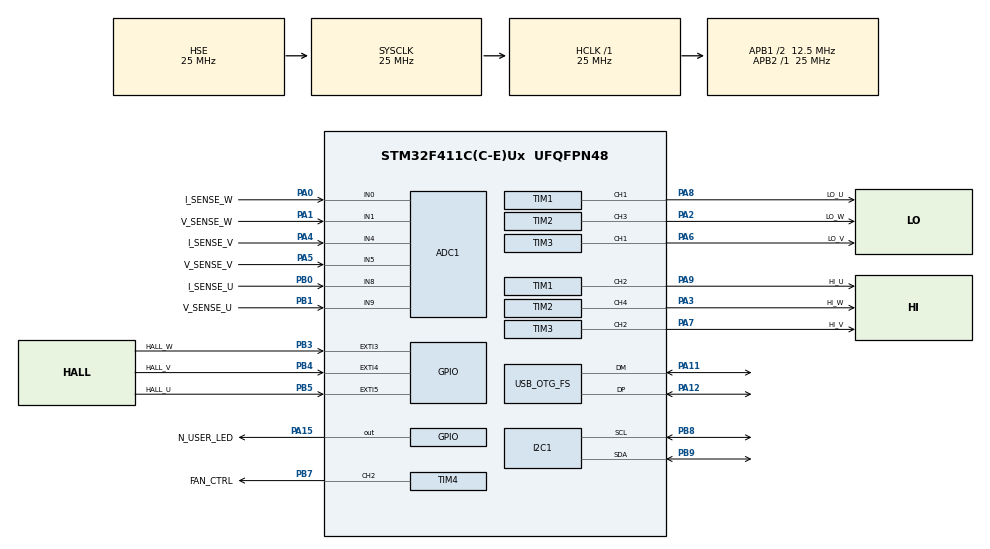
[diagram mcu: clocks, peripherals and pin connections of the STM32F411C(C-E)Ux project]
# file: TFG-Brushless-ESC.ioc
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ADC1.Channel-2\#ChannelRegularConversion=ADC_CHANNEL_0
ADC1.NbrOfConversionFlag=1
ADC1.Rank-2\#ChannelRegularConversion=1
ADC1.SamplingTime-2\#ChannelRegularConversion=ADC_SAMPLETIME_3CYCLES
ADC1.master=1
Mcu.Family=STM32F4
Mcu.Name=STM32F411C(C-E)Ux
Mcu.Package=UFQFPN48
NVIC.EXTI9_5_IRQn=true\:0\:0\:false\:false\:true\:true\:true\:true
NVIC.OTG_FS_IRQn=true\:0\:0\:false\:false\:true\:false\:true\:true
NVIC.PriorityGroup=NVIC_PRIORITYGROUP_4
PA0-WKUP.GPIO_Label=I_SENSE_W
PA0-WKUP.Signal=ADCx_IN0
PA1.GPIO_Label=V_SENSE_W
PA1.Signal=ADCx_IN1
PA11.Mode=Device_Only
PA11.Signal=USB_OTG_FS_DM
PA12.Mode=Device_Only
PA12.Signal=USB_OTG_FS_DP
PA13.Mode=Serial_Wire
PA13.Signal=SYS_JTMS-SWDIO
PA14.Mode=Serial_Wire
PA14.Signal=SYS_JTCK-SWCLK
PA15.GPIO_Label=N_USER_LED
PA15.Signal=GPIO_Output
PA2.GPIO_Label=LO_W
PA2.Signal=S_TIM2_CH3
PA3.GPIO_Label=HI_W
PA3.Signal=S_TIM2_CH4
PA4.GPIO_Label=I_SENSE_V
PA4.Signal=ADCx_IN4
PA5.GPIO_Label=V_SENSE_V
PA5.Signal=ADCx_IN5
PA6.GPIO_Label=LO_V
PA6.Signal=S_TIM3_CH1
PA7.GPIO_Label=HI_V
PA7.Signal=S_TIM3_CH2
PA8.GPIO_Label=LO_U
PA8.Signal=S_TIM1_CH1
PA9.GPIO_Label=HI_U
PA9.Signal=S_TIM1_CH2
PB0.GPIO_Label=I_SENSE_U
PB0.Signal=ADCx_IN8
PB1.GPIO_Label=V_SENSE_U
PB1.Signal=ADCx_IN9
PB3.GPIO_Label=HALL_W
PB3.Signal=GPXTI3
PB4.GPIO_Label=HALL_V
PB4.Signal=GPXTI4
PB5.GPIO_Label=HALL_U
PB5.Signal=GPXTI5
PB7.GPIO_Label=FAN_CTRL
PB7.Signal=S_TIM4_CH2
PB8.Mode=I2C
PB8.Signal=I2C1_SCL
PB9.Mode=I2C
PB9.Signal=I2C1_SDA
PC14-OSC32_IN.Mode=LSE-External-Oscillator
PC14-OSC32_IN.Signal=RCC_OSC32_IN
PC15-OSC32_OUT.Mode=LSE-External-Oscillator
PC15-OSC32_OUT.Signal=RCC_OSC32_OUT
PH0\ -\ OSC_IN.Mode=HSE-External-Oscillator
PH0\ -\ OSC_IN.Signal=RCC_OSC_IN
PH1\ -\ OSC_OUT.Mode=HSE-External-Oscillator
PH1\ -\ OSC_OUT.Signal=RCC_OSC_OUT
ProjectManager.HeapSize=0x200
ProjectManager.StackSize=0x400
ProjectManager.TargetToolchain=STM32CubeIDE
RCC.48MHZClocksFreq_Value=48000000
RCC.AHBFreq_Value=25000000
RCC.APB1CLKDivider=RCC_HCLK_DIV2
RCC.APB1Freq_Value=12500000
RCC.APB1TimFreq_Value=25000000
RCC.APB2Freq_Value=25000000
RCC.APB2TimFreq_Value=25000000
RCC.CortexFreq_Value=25000000
RCC.HCLKFreq_Value=25000000
RCC.HSE_VALUE=25000000
RCC.HSI_VALUE=16000000
RCC.PLLM=25
RCC.PLLN=144
RCC.PLLP=RCC_PLLP_DIV6
RCC.PLLQ=3
RCC.SYSCLKFreq_VALUE=25000000
RCC.SYSCLKSource=RCC_SYSCLKSOURCE_HSE
RCC.VCOOutputFreq_Value=144000000
SH.ADCx_IN0.0=ADC1_IN0,IN0
SH.ADCx_IN1.0=ADC1_IN1,IN1
SH.ADCx_IN4.0=ADC1_IN4,IN4
SH.ADCx_IN5.0=ADC1_IN5,IN5
SH.ADCx_IN8.0=ADC1_IN8,IN8
SH.ADCx_IN9.0=ADC1_IN9,IN9
SH.S_TIM1_CH1.0=TIM1_CH1,PWM Generation1 CH1
SH.S_TIM1_CH2.0=TIM1_CH2,PWM Generation2 CH2
SH.S_TIM2_CH3.0=TIM2_CH3,PWM Generation3 CH3
SH.S_TIM2_CH4.0=TIM2_CH4,PWM Generation4 CH4
SH.S_TIM3_CH1.0=TIM3_CH1,PWM Generation1 CH1
SH.S_TIM3_CH2.0=TIM3_CH2,PWM Generation2 CH2
SH.S_TIM4_CH2.0=TIM4_CH2,PWM Generation2 CH2
TIM1.Channel-PWM\ Generation1\ CH1=TIM_CHANNEL_1
TIM1.Channel-PWM\ Generation2\ CH2=TIM_CHANNEL_2
TIM2.Channel-PWM\ Generation3\ CH3=TIM_CHANNEL_3
TIM2.Channel-PWM\ Generation4\ CH4=TIM_CHANNEL_4
TIM3.Channel-PWM\ Generation1\ CH1=TIM_CHANNEL_1
TIM3.Channel-PWM\ Generation2\ CH2=TIM_CHANNEL_2
TIM3.Period=255
TIM3.Prescaler=0
TIM4.Channel-PWM\ Generation2\ CH2=TIM_CHANNEL_2
USB_DEVICE.APP_RX_DATA_SIZE=64
USB_DEVICE.CLASS_NAME_FS=CDC
USB_DEVICE.VirtualMode=Cdc
USB_DEVICE.VirtualModeFS=Cdc_FS
USB_OTG_FS.VirtualMode=Device_Only
VP_TIM1_VS_ClockSourceINT.Mode=Internal
VP_USB_DEVICE_VS_USB_DEVICE_CDC_FS.Mode=CDC_FS
board=custom

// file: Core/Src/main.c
/* USER CODE BEGIN Header */
/**
  ******************************************************************************
  * @file           : main.c
  * @brief          : Main program body
  ******************************************************************************
  * @attention
  *
  * Copyright (c) 2024 STMicroelectronics.
  * All rights reserved.
  *
  * This software is licensed under terms that can be found in the LICENSE file
  * in the root directory of this software component.
  * If no LICENSE file comes with this software, it is provided AS-IS.
  *
  ******************************************************************************
  */
/* USER CODE END Header */
#include "main.h"
#include "usb_device.h"

/* USER CODE BEGIN Includes */
#include "RTSpeed/RTSpeed.h"
#include "RTSpeed/Analog.h"
/* USER CODE END Includes */

ADC_HandleTypeDef hadc1;

I2C_HandleTypeDef hi2c1;

TIM_HandleTypeDef htim1;
TIM_HandleTypeDef htim2;
TIM_HandleTypeDef htim3;
TIM_HandleTypeDef htim4;

void SystemClock_Config(void);
static void MX_GPIO_Init(void);
static void MX_ADC1_Init(void);
static void MX_I2C1_Init(void);
static void MX_TIM3_Init(void);
static void MX_TIM1_Init(void);
static void MX_TIM2_Init(void);
static void MX_TIM4_Init(void);

int main(void)
{

  /* MCU Configuration--------------------------------------------------------*/

  /* Reset of all peripherals, Initializes the Flash interface and the Systick. */
  HAL_Init();

  /* Configure the system clock */
  SystemClock_Config();

  /* Initialize all configured peripherals */
  MX_GPIO_Init();
  MX_USB_DEVICE_Init();
  MX_ADC1_Init();
  MX_I2C1_Init();
  MX_TIM3_Init();
  MX_TIM1_Init();
  MX_TIM2_Init();
  MX_TIM4_Init();
  /* USER CODE BEGIN 2 */

  HAL_TIM_PWM_Start(&htim2, TIM_CHANNEL_1);
  HAL_TIM_PWM_Start(&htim2, TIM_CHANNEL_3);
  HAL_TIM_PWM_Start(&htim3, TIM_CHANNEL_1);
  HAL_TIM_PWM_Start(&htim3, TIM_CHANNEL_4);
  HAL_TIM_PWM_Start(&htim4, TIM_CHANNEL_1);
  HAL_TIM_PWM_Start(&htim4, TIM_CHANNEL_2);

  HAL_ADC_Start_IT(&hadc1);

  /* USER CODE END 2 */

  /* Infinite loop */
  while (1)
  {

    /* USER CODE BEGIN 3 */

  } // !while
  /* USER CODE END 3 */
}

void SystemClock_Config(void)
{
  RCC_OscInitTypeDef RCC_OscInitStruct = {0};
  RCC_ClkInitTypeDef RCC_ClkInitStruct = {0};

  /** Configure the main internal regulator output voltage
  */
  __HAL_RCC_PWR_CLK_ENABLE();
  __HAL_PWR_VOLTAGESCALING_CONFIG(PWR_REGULATOR_VOLTAGE_SCALE1);

  /** Initializes the RCC Oscillators according to the specified parameters
  * in the RCC_OscInitTypeDef structure.
  */
  RCC_OscInitStruct.OscillatorType = RCC_OSCILLATORTYPE_HSE;
  RCC_OscInitStruct.HSEState = RCC_HSE_ON;
  RCC_OscInitStruct.PLL.PLLState = RCC_PLL_ON;
  RCC_OscInitStruct.PLL.PLLSource = RCC_PLLSOURCE_HSE;
  RCC_OscInitStruct.PLL.PLLM = 25;
  RCC_OscInitStruct.PLL.PLLN = 144;
  RCC_OscInitStruct.PLL.PLLP = RCC_PLLP_DIV6;
  RCC_OscInitStruct.PLL.PLLQ = 3;
  if (HAL_RCC_OscConfig(&RCC_OscInitStruct) != HAL_OK)
  {
    Error_Handler();
  }

  /** Initializes the CPU, AHB and APB buses clocks
  */
  RCC_ClkInitStruct.ClockType = RCC_CLOCKTYPE_HCLK|RCC_CLOCKTYPE_SYSCLK
                              |RCC_CLOCKTYPE_PCLK1|RCC_CLOCKTYPE_PCLK2;
  RCC_ClkInitStruct.SYSCLKSource = RCC_SYSCLKSOURCE_HSE;
  RCC_ClkInitStruct.AHBCLKDivider = RCC_SYSCLK_DIV1;
  RCC_ClkInitStruct.APB1CLKDivider = RCC_HCLK_DIV2;
  RCC_ClkInitStruct.APB2CLKDivider = RCC_HCLK_DIV1;

  if (HAL_RCC_ClockConfig(&RCC_ClkInitStruct, FLASH_LATENCY_0) != HAL_OK)
  {
    Error_Handler();
  }
}

static void MX_ADC1_Init(void)
{

  ADC_ChannelConfTypeDef sConfig = {0};

  /** Configure the global features of the ADC (Clock, Resolution, Data Alignment and number of conversion)
  */
  hadc1.Instance = ADC1;
  hadc1.Init.ClockPrescaler = ADC_CLOCK_SYNC_PCLK_DIV2;
  hadc1.Init.Resolution = ADC_RESOLUTION_12B;
  hadc1.Init.ScanConvMode = DISABLE;
  hadc1.Init.ContinuousConvMode = DISABLE;
  hadc1.Init.DiscontinuousConvMode = DISABLE;
  hadc1.Init.ExternalTrigConvEdge = ADC_EXTERNALTRIGCONVEDGE_NONE;
  hadc1.Init.ExternalTrigConv = ADC_SOFTWARE_START;
  hadc1.Init.DataAlign = ADC_DATAALIGN_RIGHT;
  hadc1.Init.NbrOfConversion = 1;
  hadc1.Init.DMAContinuousRequests = DISABLE;
  hadc1.Init.EOCSelection = ADC_EOC_SINGLE_CONV;
  if (HAL_ADC_Init(&hadc1) != HAL_OK)
  {
    Error_Handler();
  }

  /** Configure for the selected ADC regular channel its corresponding rank in the sequencer and its sample time.
  */
  sConfig.Channel = ADC_CHANNEL_0;
  sConfig.Rank = 1;
  sConfig.SamplingTime = ADC_SAMPLETIME_3CYCLES;
  if (HAL_ADC_ConfigChannel(&hadc1, &sConfig) != HAL_OK)
  {
    Error_Handler();
  }

}

static void MX_I2C1_Init(void)
{

  hi2c1.Instance = I2C1;
  hi2c1.Init.ClockSpeed = 100000;
  hi2c1.Init.DutyCycle = I2C_DUTYCYCLE_2;
  hi2c1.Init.OwnAddress1 = 0;
  hi2c1.Init.AddressingMode = I2C_ADDRESSINGMODE_7BIT;
  hi2c1.Init.DualAddressMode = I2C_DUALADDRESS_DISABLE;
  hi2c1.Init.OwnAddress2 = 0;
  hi2c1.Init.GeneralCallMode = I2C_GENERALCALL_DISABLE;
  hi2c1.Init.NoStretchMode = I2C_NOSTRETCH_DISABLE;
  if (HAL_I2C_Init(&hi2c1) != HAL_OK)
  {
    Error_Handler();
  }

}

static void MX_TIM1_Init(void)
{

  TIM_ClockConfigTypeDef sClockSourceConfig = {0};
  TIM_MasterConfigTypeDef sMasterConfig = {0};
  TIM_OC_InitTypeDef sConfigOC = {0};
  TIM_BreakDeadTimeConfigTypeDef sBreakDeadTimeConfig = {0};

  htim1.Instance = TIM1;
  htim1.Init.Prescaler = 0;
  htim1.Init.CounterMode = TIM_COUNTERMODE_UP;
  htim1.Init.Period = 65535;
  htim1.Init.ClockDivision = TIM_CLOCKDIVISION_DIV1;
  htim1.Init.RepetitionCounter = 0;
  htim1.Init.AutoReloadPreload = TIM_AUTORELOAD_PRELOAD_DISABLE;
  if (HAL_TIM_Base_Init(&htim1) != HAL_OK)
  {
    Error_Handler();
  }
  sClockSourceConfig.ClockSource = TIM_CLOCKSOURCE_INTERNAL;
  if (HAL_TIM_ConfigClockSource(&htim1, &sClockSourceConfig) != HAL_OK)
  {
    Error_Handler();
  }
  if (HAL_TIM_PWM_Init(&htim1) != HAL_OK)
  {
    Error_Handler();
  }
  sMasterConfig.MasterOutputTrigger = TIM_TRGO_RESET;
  sMasterConfig.MasterSlaveMode = TIM_MASTERSLAVEMODE_DISABLE;
  if (HAL_TIMEx_MasterConfigSynchronization(&htim1, &sMasterConfig) != HAL_OK)
  {
    Error_Handler();
  }
  sConfigOC.OCMode = TIM_OCMODE_PWM1;
  sConfigOC.Pulse = 0;
  sConfigOC.OCPolarity = TIM_OCPOLARITY_HIGH;
  sConfigOC.OCNPolarity = TIM_OCNPOLARITY_HIGH;
  sConfigOC.OCFastMode = TIM_OCFAST_DISABLE;
  sConfigOC.OCIdleState = TIM_OCIDLESTATE_RESET;
  sConfigOC.OCNIdleState = TIM_OCNIDLESTATE_RESET;
  if (HAL_TIM_PWM_ConfigChannel(&htim1, &sConfigOC, TIM_CHANNEL_1) != HAL_OK)
  {
    Error_Handler();
  }
  if (HAL_TIM_PWM_ConfigChannel(&htim1, &sConfigOC, TIM_CHANNEL_2) != HAL_OK)
  {
    Error_Handler();
  }
  sBreakDeadTimeConfig.OffStateRunMode = TIM_OSSR_DISABLE;
  sBreakDeadTimeConfig.OffStateIDLEMode = TIM_OSSI_DISABLE;
  sBreakDeadTimeConfig.LockLevel = TIM_LOCKLEVEL_OFF;
  sBreakDeadTimeConfig.DeadTime = 0;
  sBreakDeadTimeConfig.BreakState = TIM_BREAK_DISABLE;
  sBreakDeadTimeConfig.BreakPolarity = TIM_BREAKPOLARITY_HIGH;
  sBreakDeadTimeConfig.AutomaticOutput = TIM_AUTOMATICOUTPUT_DISABLE;
  if (HAL_TIMEx_ConfigBreakDeadTime(&htim1, &sBreakDeadTimeConfig) != HAL_OK)
  {
    Error_Handler();
  }
  HAL_TIM_MspPostInit(&htim1);

}

static void MX_TIM2_Init(void)
{

  TIM_MasterConfigTypeDef sMasterConfig = {0};
  TIM_OC_InitTypeDef sConfigOC = {0};

  htim2.Instance = TIM2;
  htim2.Init.Prescaler = 0;
  htim2.Init.CounterMode = TIM_COUNTERMODE_UP;
  htim2.Init.Period = 4294967295;
  htim2.Init.ClockDivision = TIM_CLOCKDIVISION_DIV1;
  htim2.Init.AutoReloadPreload = TIM_AUTORELOAD_PRELOAD_DISABLE;
  if (HAL_TIM_PWM_Init(&htim2) != HAL_OK)
  {
    Error_Handler();
  }
  sMasterConfig.MasterOutputTrigger = TIM_TRGO_RESET;
  sMasterConfig.MasterSlaveMode = TIM_MASTERSLAVEMODE_DISABLE;
  if (HAL_TIMEx_MasterConfigSynchronization(&htim2, &sMasterConfig) != HAL_OK)
  {
    Error_Handler();
  }
  sConfigOC.OCMode = TIM_OCMODE_PWM1;
  sConfigOC.Pulse = 0;
  sConfigOC.OCPolarity = TIM_OCPOLARITY_HIGH;
  sConfigOC.OCFastMode = TIM_OCFAST_DISABLE;
  if (HAL_TIM_PWM_ConfigChannel(&htim2, &sConfigOC, TIM_CHANNEL_3) != HAL_OK)
  {
    Error_Handler();
  }
  if (HAL_TIM_PWM_ConfigChannel(&htim2, &sConfigOC, TIM_CHANNEL_4) != HAL_OK)
  {
    Error_Handler();
  }
  HAL_TIM_MspPostInit(&htim2);

}

static void MX_TIM3_Init(void)
{

  TIM_MasterConfigTypeDef sMasterConfig = {0};
  TIM_OC_InitTypeDef sConfigOC = {0};

  htim3.Instance = TIM3;
  htim3.Init.Prescaler = 0;
  htim3.Init.CounterMode = TIM_COUNTERMODE_UP;
  htim3.Init.Period = 255;
  htim3.Init.ClockDivision = TIM_CLOCKDIVISION_DIV1;
  htim3.Init.AutoReloadPreload = TIM_AUTORELOAD_PRELOAD_DISABLE;
  if (HAL_TIM_PWM_Init(&htim3) != HAL_OK)
  {
    Error_Handler();
  }
  sMasterConfig.MasterOutputTrigger = TIM_TRGO_RESET;
  sMasterConfig.MasterSlaveMode = TIM_MASTERSLAVEMODE_DISABLE;
  if (HAL_TIMEx_MasterConfigSynchronization(&htim3, &sMasterConfig) != HAL_OK)
  {
    Error_Handler();
  }
  sConfigOC.OCMode = TIM_OCMODE_PWM1;
  sConfigOC.Pulse = 0;
  sConfigOC.OCPolarity = TIM_OCPOLARITY_HIGH;
  sConfigOC.OCFastMode = TIM_OCFAST_DISABLE;
  if (HAL_TIM_PWM_ConfigChannel(&htim3, &sConfigOC, TIM_CHANNEL_1) != HAL_OK)
  {
    Error_Handler();
  }
  if (HAL_TIM_PWM_ConfigChannel(&htim3, &sConfigOC, TIM_CHANNEL_2) != HAL_OK)
  {
    Error_Handler();
  }
  HAL_TIM_MspPostInit(&htim3);

}

static void MX_TIM4_Init(void)
{

  TIM_MasterConfigTypeDef sMasterConfig = {0};
  TIM_OC_InitTypeDef sConfigOC = {0};

  htim4.Instance = TIM4;
  htim4.Init.Prescaler = 0;
  htim4.Init.CounterMode = TIM_COUNTERMODE_UP;
  htim4.Init.Period = 65535;
  htim4.Init.ClockDivision = TIM_CLOCKDIVISION_DIV1;
  htim4.Init.AutoReloadPreload = TIM_AUTORELOAD_PRELOAD_DISABLE;
  if (HAL_TIM_PWM_Init(&htim4) != HAL_OK)
  {
    Error_Handler();
  }
  sMasterConfig.MasterOutputTrigger = TIM_TRGO_RESET;
  sMasterConfig.MasterSlaveMode = TIM_MASTERSLAVEMODE_DISABLE;
  if (HAL_TIMEx_MasterConfigSynchronization(&htim4, &sMasterConfig) != HAL_OK)
  {
    Error_Handler();
  }
  sConfigOC.OCMode = TIM_OCMODE_PWM1;
  sConfigOC.Pulse = 0;
  sConfigOC.OCPolarity = TIM_OCPOLARITY_HIGH;
  sConfigOC.OCFastMode = TIM_OCFAST_DISABLE;
  if (HAL_TIM_PWM_ConfigChannel(&htim4, &sConfigOC, TIM_CHANNEL_2) != HAL_OK)
  {
    Error_Handler();
  }
  HAL_TIM_MspPostInit(&htim4);

}

static void MX_GPIO_Init(void)
{
  GPIO_InitTypeDef GPIO_InitStruct = {0};

  /* GPIO Ports Clock Enable */
  __HAL_RCC_GPIOC_CLK_ENABLE();
  __HAL_RCC_GPIOH_CLK_ENABLE();
  __HAL_RCC_GPIOA_CLK_ENABLE();
  __HAL_RCC_GPIOB_CLK_ENABLE();

  /*Configure GPIO pin Output Level */
  HAL_GPIO_WritePin(N_USER_LED_GPIO_Port, N_USER_LED_Pin, GPIO_PIN_RESET);

  /*Configure GPIO pin : N_USER_LED_Pin */
  GPIO_InitStruct.Pin = N_USER_LED_Pin;
  GPIO_InitStruct.Mode = GPIO_MODE_OUTPUT_PP;
  GPIO_InitStruct.Pull = GPIO_NOPULL;
  GPIO_InitStruct.Speed = GPIO_SPEED_FREQ_LOW;
  HAL_GPIO_Init(N_USER_LED_GPIO_Port, &GPIO_InitStruct);

  /*Configure GPIO pins : HALL_W_Pin HALL_V_Pin HALL_U_Pin */
  GPIO_InitStruct.Pin = HALL_W_Pin|HALL_V_Pin|HALL_U_Pin;
  GPIO_InitStruct.Mode = GPIO_MODE_IT_RISING;
  GPIO_InitStruct.Pull = GPIO_NOPULL;
  HAL_GPIO_Init(GPIOB, &GPIO_InitStruct);

  /* EXTI interrupt init*/
  HAL_NVIC_SetPriority(EXTI9_5_IRQn, 0, 0);
  HAL_NVIC_EnableIRQ(EXTI9_5_IRQn);

}

void Error_Handler(void)
{
  __disable_irq();
  while (1)
  {
  }
}
